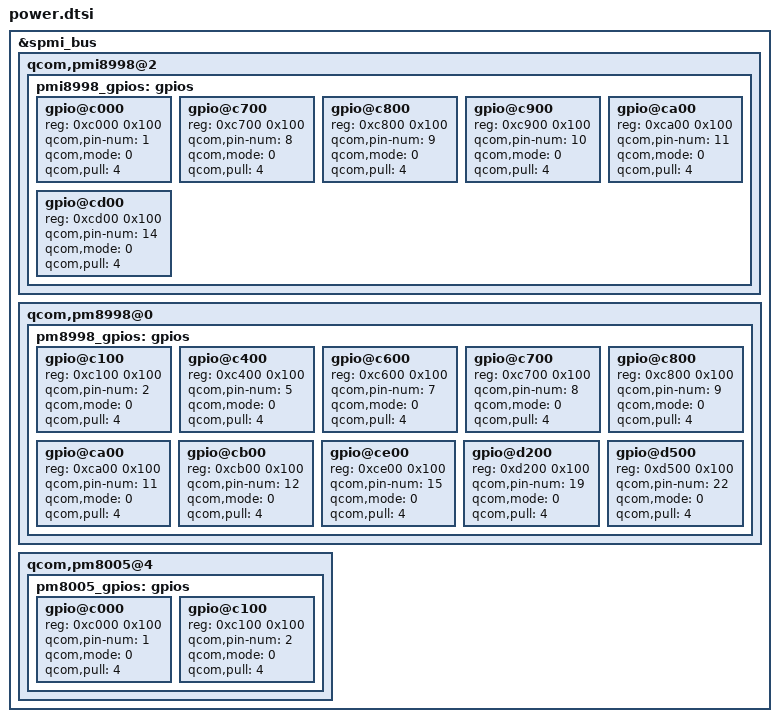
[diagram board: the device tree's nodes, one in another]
/* Unused GPIOs PMI8998 */
&spmi_bus {
	qcom,pmi8998@2 {
		pmi8998_gpios: gpios {
			gpio@c000 {
				reg = <0xc000 0x100>;
				qcom,pin-num = <1>;
				qcom,mode = <0>;
				qcom,pull = <4>;
				status = "okay";
			};

			gpio@c700 {
				reg = <0xc700 0x100>;
				qcom,pin-num = <8>;
				qcom,mode = <0>;
				qcom,pull = <4>;
				status = "okay";
			};

			gpio@c800 {
				reg = <0xc800 0x100>;
				qcom,pin-num = <9>;
				qcom,mode = <0>;
				qcom,pull = <4>;
				status = "okay";
			};

			gpio@c900 {
				reg = <0xc900 0x100>;
				qcom,pin-num = <10>;
				qcom,mode = <0>;
				qcom,pull = <4>;
				status = "okay";
			};

			gpio@ca00 {
				reg = <0xca00 0x100>;
				qcom,pin-num = <11>;
				qcom,mode = <0>;
				qcom,pull = <4>;
				status = "okay";
			};

			gpio@cd00 {
				reg = <0xcd00 0x100>;
				qcom,pin-num = <14>;
				qcom,mode = <0>;
				qcom,pull = <4>;
				status = "okay";
			};
		};
	};
};

/* Unused GPIOs PM8998 */
&spmi_bus {
	qcom,pm8998@0 {
		pm8998_gpios: gpios {
			gpio@c100 {
				reg = <0xc100 0x100>;
				qcom,pin-num = <2>;
				qcom,mode = <0>;
				qcom,pull = <4>;
				status = "okay";
			};

			gpio@c400 {
				reg = <0xc400 0x100>;
				qcom,pin-num = <5>;
				qcom,mode = <0>;
				qcom,pull = <4>;
				status = "okay";
			};

			gpio@c600 {
				reg = <0xc600 0x100>;
				qcom,pin-num = <7>;
				qcom,mode = <0>;
				qcom,pull = <4>;
				status = "okay";
			};

			gpio@c700 {
				reg = <0xc700 0x100>;
				qcom,pin-num = <8>;
				qcom,mode = <0>;
				qcom,pull = <4>;
				status = "okay";
			};

			gpio@c800 {
				reg = <0xc800 0x100>;
				qcom,pin-num = <9>;
				qcom,mode = <0>;
				qcom,pull = <4>;
				status = "okay";
			};

			gpio@ca00 {
				reg = <0xca00 0x100>;
				qcom,pin-num = <11>;
				qcom,mode = <0>;
				qcom,pull = <4>;
				status = "okay";
			};

			gpio@cb00 {
				reg = <0xcb00 0x100>;
				qcom,pin-num = <12>;
				qcom,mode = <0>;
				qcom,pull = <4>;
				status = "okay";
			};

			gpio@ce00 {
				reg = <0xce00 0x100>;
				qcom,pin-num = <15>;
				qcom,mode = <0>;
				qcom,pull = <4>;
				status = "okay";
			};

			gpio@d200 {
				reg = <0xd200 0x100>;
				qcom,pin-num = <19>;
				qcom,mode = <0>;
				qcom,pull = <4>;
				status = "okay";
			};

			gpio@d500 {
				reg = <0xd500 0x100>;
				qcom,pin-num = <22>;
				qcom,mode = <0>;
				qcom,pull = <4>;
				status = "okay";
			};
		};
	};
};

/* Unused GPIOs PM8005 */
&spmi_bus {
	qcom,pm8005@4 {
		pm8005_gpios: gpios {
			gpio@c000 {
				reg = <0xc000 0x100>;
				qcom,pin-num = <1>;
				qcom,mode = <0>;
				qcom,pull = <4>;
				status = "okay";
			};

			gpio@c100 {
				reg = <0xc100 0x100>;
				qcom,pin-num = <2>;
				qcom,mode = <0>;
				qcom,pull = <4>;
				status = "okay";
			};
		};
	};
};
